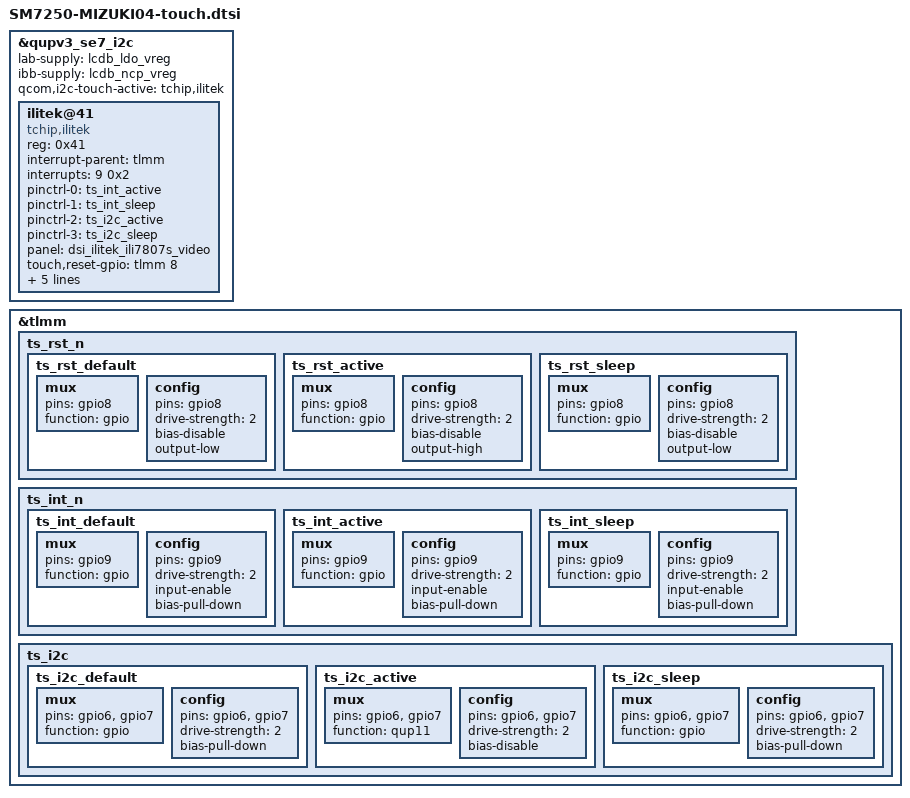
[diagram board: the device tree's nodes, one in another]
/*
 * This software is contributed or developed by KYOCERA Corporation.
 * (C) 2020 KYOCERA Corporation
 *
 * This program is free software; you can redistribute it and/or modify
 * it under the terms of the GNU General Public License version 2 and
 * only version 2 as published by the Free Software Foundation.
 *
 * This program is distributed in the hope that it will be useful,
 * but WITHOUT ANY WARRANTY; without even the implied warranty of
 * MERCHANTABILITY or FITNESS FOR A PARTICULAR PURPOSE.  See the
 * GNU General Public License for more details.
 */

&qupv3_se7_i2c {
	#address-cells = <1>;
	#size-cells = <0>;

	status = "ok";

	lab-supply = <&lcdb_ldo_vreg>;
	ibb-supply = <&lcdb_ncp_vreg>;

	qcom,i2c-touch-active = "tchip,ilitek";

	ilitek@41 {
		compatible = "tchip,ilitek";
		reg = <0x41>;
		interrupt-parent = <&tlmm>;
		interrupts = <9 0x2>;
		pinctrl-names = "pmx_ts_active", "pmx_ts_sleep", "ts_i2c_active", "ts_i2c_sleep";
		pinctrl-0 = <&ts_int_active>;
		pinctrl-1 = <&ts_int_sleep>;
		pinctrl-2 = <&ts_i2c_active>;
		pinctrl-3 = <&ts_i2c_sleep>;

		panel = <&dsi_ilitek_ili7807s_video>;

//		vdd-supply = <&pm8953_l10>;
//		vcc_i2c-supply = <&pm8953_l6>;
		touch,reset-gpio = <&tlmm 8 0x0>;
		touch,irq-gpio = <&tlmm 9 0x2008>;
		ilitek,vbus = "vcc_i2c";
		ilitek,vdd = "vdd";
		ilitek,name = "ilitek_i2c";
		kc,func_mode = <3>;

	};

};

&tlmm {
	ts_rst_n {
		ts_rst_default: ts_rst_default {
			mux {
				pins = "gpio8";
				function = "gpio";
			};

			config {
				pins = "gpio8";
				drive-strength = <2>;
				bias-disable;
				output-low;
			};
		};
		ts_rst_active: ts_rst_active {
			mux {
				pins = "gpio8";
				function = "gpio";
			};

			config {
				pins = "gpio8";
				drive-strength = <2>;
				bias-disable;
				output-high;
			};
		};
		ts_rst_sleep: ts_rst_sleep {
			mux {
				pins = "gpio8";
				function = "gpio";
			};

			config {
				pins = "gpio8";
				drive-strength = <2>;
				bias-disable;
				output-low;
			};
		};
	};

	ts_int_n {
		ts_int_default: ts_int_default {
			mux {
				pins = "gpio9";
				function = "gpio";
			};

			config {
				pins = "gpio9";
				drive-strength = <2>;
				input-enable;
				bias-pull-down;
			};
		};
		ts_int_active: ts_int_active {
			mux {
				pins = "gpio9";
				function = "gpio";
			};

			config {
				pins = "gpio9";
				drive-strength = <2>;
				input-enable;
				bias-pull-down;
			};
		};
		ts_int_sleep: ts_int_sleep {
			mux {
				pins = "gpio9";
				function = "gpio";
			};

			config {
				pins = "gpio9";
				drive-strength = <2>;
				input-enable;
				bias-pull-down;
			};
		};
	};

    ts_i2c {
        ts_i2c_default: ts_i2c_default {
            mux {
                pins = "gpio6", "gpio7";
                function = "gpio";
            };
            config {
                pins = "gpio6", "gpio7";
                drive-strength = <2>;
                bias-pull-down;
            };
        };
        ts_i2c_active: ts_i2c_active {
            mux {
                pins = "gpio6", "gpio7";
                function = "qup11";
            };
            config {
                pins = "gpio6", "gpio7";
                drive-strength = <2>;
                bias-disable;
            };
        };
        ts_i2c_sleep: ts_i2c_sleep {
            mux {
                pins = "gpio6", "gpio7";
                function = "gpio";
            };
            config {
                pins = "gpio6", "gpio7";
                drive-strength = <2>;
                bias-pull-down;
            };
        };
    };
};
